# Espressif register map
File version: 1.0
CPU: Xtensa LX6 1, little endian, no MPU, FPU, 3 interrupt priority bits
Registers are 32-bit, access not given, reset 0x0 unless marked. A register's access mark holds for its fields unless they carry their own. Offsets are from the block's base; [hi:lo] are bit positions; {n}, {i} and the like mark numbered series.

## SENS
Base 0x3FF48800
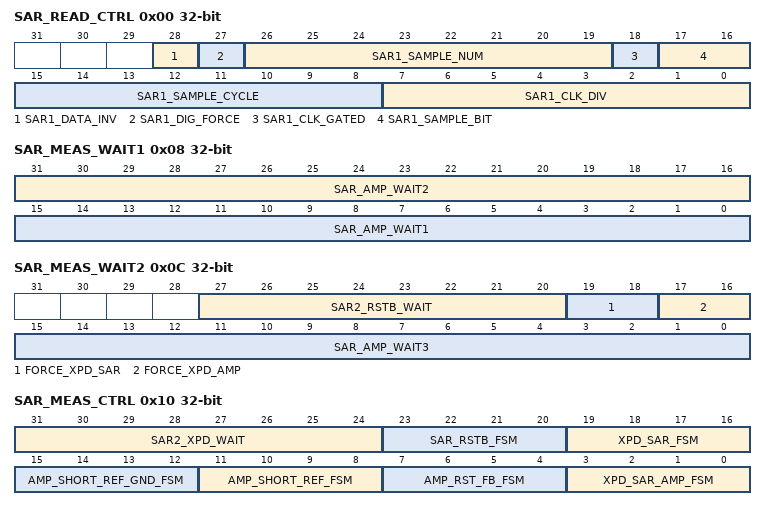
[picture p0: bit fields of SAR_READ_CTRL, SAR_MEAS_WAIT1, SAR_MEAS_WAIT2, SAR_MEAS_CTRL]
0x00 SAR_READ_CTRL — SENS_SAR_READ_CTRL
  [28] SAR1_DATA_INV, [27] SAR1_DIG_FORCE, [26:19] SAR1_SAMPLE_NUM, [18] SAR1_CLK_GATED, [17:16] SAR1_SAMPLE_BIT, [15:8] SAR1_SAMPLE_CYCLE, [7:0] SAR1_CLK_DIV
0x04 SAR_READ_STATUS1 — SENS_SAR_READ_STATUS1
  [31:0] SAR1_READER_STATUS
0x08 SAR_MEAS_WAIT1 — SENS_SAR_MEAS_WAIT1
  [31:16] SAR_AMP_WAIT2, [15:0] SAR_AMP_WAIT1
0x0C SAR_MEAS_WAIT2 — SENS_SAR_MEAS_WAIT2
  [27:20] SAR2_RSTB_WAIT, [19:18] FORCE_XPD_SAR, [17:16] FORCE_XPD_AMP, [15:0] SAR_AMP_WAIT3
0x10 SAR_MEAS_CTRL — SENS_SAR_MEAS_CTRL
  [31:24] SAR2_XPD_WAIT, [23:20] SAR_RSTB_FSM, [19:16] XPD_SAR_FSM, [15:12] AMP_SHORT_REF_GND_FSM, [11:8] AMP_SHORT_REF_FSM, [7:4] AMP_RST_FB_FSM, [3:0] XPD_SAR_AMP_FSM
0x14 SAR_READ_STATUS2 — SENS_SAR_READ_STATUS2
  [31:0] SAR2_READER_STATUS
{0x18+4i} ULP_CP_SLEEP_CYC{i} (i=0..4) — SENS_ULP_CP_SLEEP_CYC{i}
  [31:0] SLEEP_CYCLES_S{i}
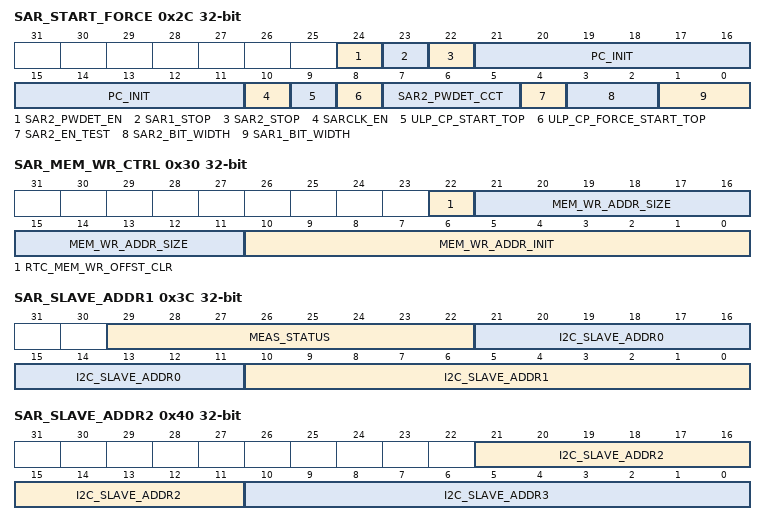
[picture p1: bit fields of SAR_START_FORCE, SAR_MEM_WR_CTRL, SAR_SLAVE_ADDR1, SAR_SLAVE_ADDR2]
0x2C SAR_START_FORCE — SENS_SAR_START_FORCE
  [24] SAR2_PWDET_EN, [23] SAR1_STOP, [22] SAR2_STOP, [21:11] PC_INIT, [10] SARCLK_EN, [9] ULP_CP_START_TOP, [8] ULP_CP_FORCE_START_TOP, [7:5] SAR2_PWDET_CCT, [4] SAR2_EN_TEST, [3:2] SAR2_BIT_WIDTH, [1:0] SAR1_BIT_WIDTH
0x30 SAR_MEM_WR_CTRL — SENS_SAR_MEM_WR_CTRL
  [22] RTC_MEM_WR_OFFST_CLR, [21:11] MEM_WR_ADDR_SIZE, [10:0] MEM_WR_ADDR_INIT
0x34 SAR_ATTEN1 — SENS_SAR_ATTEN1
  [31:0] SAR1_ATTEN
0x38 SAR_ATTEN2 — SENS_SAR_ATTEN2
  [31:0] SAR2_ATTEN
0x3C SAR_SLAVE_ADDR1 — SENS_SAR_SLAVE_ADDR1
  [29:22] MEAS_STATUS, [21:11] I2C_SLAVE_ADDR0, [10:0] I2C_SLAVE_ADDR1
0x40 SAR_SLAVE_ADDR2 — SENS_SAR_SLAVE_ADDR2
  [21:11] I2C_SLAVE_ADDR2, [10:0] I2C_SLAVE_ADDR3
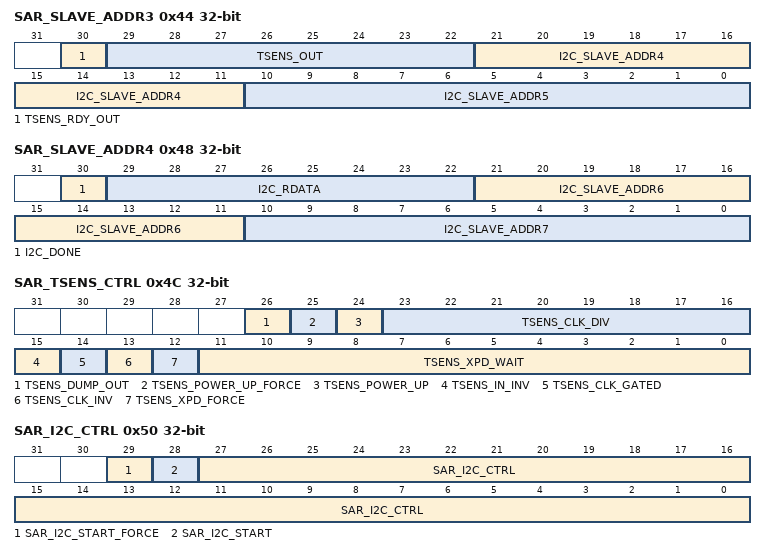
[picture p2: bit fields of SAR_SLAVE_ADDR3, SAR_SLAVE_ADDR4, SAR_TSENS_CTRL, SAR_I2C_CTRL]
0x44 SAR_SLAVE_ADDR3 — SENS_SAR_SLAVE_ADDR3
  [30] TSENS_RDY_OUT, [29:22] TSENS_OUT, [21:11] I2C_SLAVE_ADDR4, [10:0] I2C_SLAVE_ADDR5
0x48 SAR_SLAVE_ADDR4 — SENS_SAR_SLAVE_ADDR4
  [30] I2C_DONE, [29:22] I2C_RDATA, [21:11] I2C_SLAVE_ADDR6, [10:0] I2C_SLAVE_ADDR7
0x4C SAR_TSENS_CTRL — SENS_SAR_TSENS_CTRL
  [26] TSENS_DUMP_OUT, [25] TSENS_POWER_UP_FORCE, [24] TSENS_POWER_UP, [23:16] TSENS_CLK_DIV, [15] TSENS_IN_INV, [14] TSENS_CLK_GATED, [13] TSENS_CLK_INV, [12] TSENS_XPD_FORCE, [11:0] TSENS_XPD_WAIT
0x50 SAR_I2C_CTRL — SENS_SAR_I2C_CTRL
  [29] SAR_I2C_START_FORCE, [28] SAR_I2C_START, [27:0] SAR_I2C_CTRL
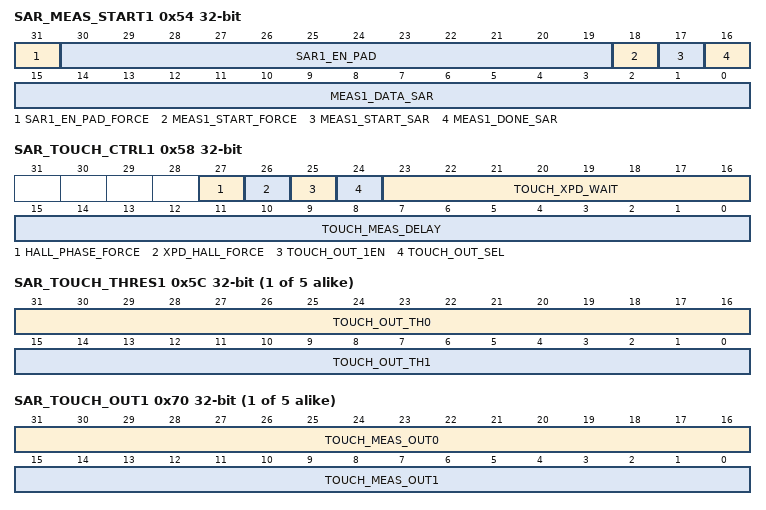
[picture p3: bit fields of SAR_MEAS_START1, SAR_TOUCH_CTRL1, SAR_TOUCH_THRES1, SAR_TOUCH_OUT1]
0x54 SAR_MEAS_START1 — SENS_SAR_MEAS_START1
  [31] SAR1_EN_PAD_FORCE, [30:19] SAR1_EN_PAD, [18] MEAS1_START_FORCE, [17] MEAS1_START_SAR, [16] MEAS1_DONE_SAR, [15:0] MEAS1_DATA_SAR
0x58 SAR_TOUCH_CTRL1 — SENS_SAR_TOUCH_CTRL1
  [27] HALL_PHASE_FORCE, [26] XPD_HALL_FORCE, [25] TOUCH_OUT_1EN, [24] TOUCH_OUT_SEL, [23:16] TOUCH_XPD_WAIT, [15:0] TOUCH_MEAS_DELAY
{0x58+4i} SAR_TOUCH_THRES{i} (i=1..5) — SENS_SAR_TOUCH_THRES{i}
  [31:16] TOUCH_OUT_TH{2i-2}, [15:0] TOUCH_OUT_TH{2i-1}
{0x6C+4i} SAR_TOUCH_OUT{i} (i=1..5) — SENS_SAR_TOUCH_OUT{i}
  [31:16] TOUCH_MEAS_OUT{2i-2}, [15:0] TOUCH_MEAS_OUT{2i-1}
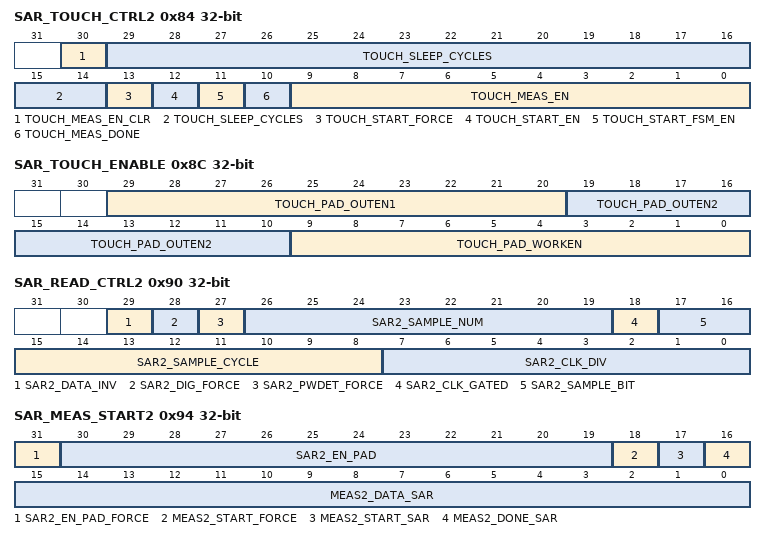
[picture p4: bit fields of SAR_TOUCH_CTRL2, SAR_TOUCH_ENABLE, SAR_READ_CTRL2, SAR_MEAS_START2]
0x84 SAR_TOUCH_CTRL2 — SENS_SAR_TOUCH_CTRL2
  [30] TOUCH_MEAS_EN_CLR, [29:14] TOUCH_SLEEP_CYCLES, [13] TOUCH_START_FORCE, [12] TOUCH_START_EN, [11] TOUCH_START_FSM_EN, [10] TOUCH_MEAS_DONE, [9:0] TOUCH_MEAS_EN
0x8C SAR_TOUCH_ENABLE — SENS_SAR_TOUCH_ENABLE
  [29:20] TOUCH_PAD_OUTEN1, [19:10] TOUCH_PAD_OUTEN2, [9:0] TOUCH_PAD_WORKEN
0x90 SAR_READ_CTRL2 — SENS_SAR_READ_CTRL2
  [29] SAR2_DATA_INV, [28] SAR2_DIG_FORCE, [27] SAR2_PWDET_FORCE, [26:19] SAR2_SAMPLE_NUM, [18] SAR2_CLK_GATED, [17:16] SAR2_SAMPLE_BIT, [15:8] SAR2_SAMPLE_CYCLE, [7:0] SAR2_CLK_DIV
0x94 SAR_MEAS_START2 — SENS_SAR_MEAS_START2
  [31] SAR2_EN_PAD_FORCE, [30:19] SAR2_EN_PAD, [18] MEAS2_START_FORCE, [17] MEAS2_START_SAR, [16] MEAS2_DONE_SAR, [15:0] MEAS2_DATA_SAR
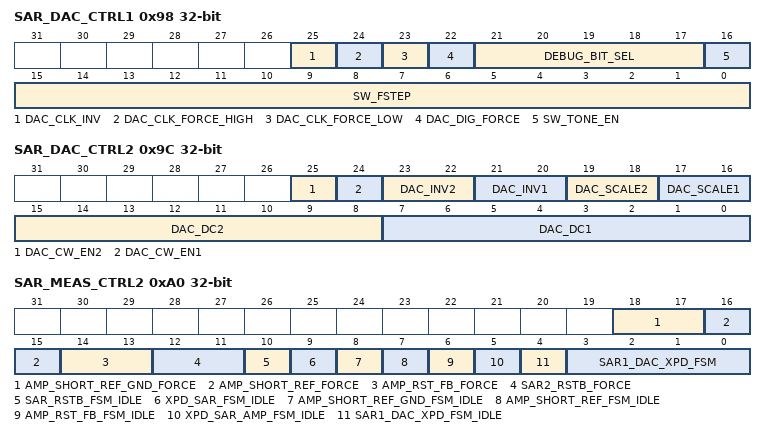
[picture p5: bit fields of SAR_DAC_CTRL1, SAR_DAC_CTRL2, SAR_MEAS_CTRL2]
0x98 SAR_DAC_CTRL1 — SENS_SAR_DAC_CTRL1
  [25] DAC_CLK_INV, [24] DAC_CLK_FORCE_HIGH, [23] DAC_CLK_FORCE_LOW, [22] DAC_DIG_FORCE, [21:17] DEBUG_BIT_SEL, [16] SW_TONE_EN, [15:0] SW_FSTEP
0x9C SAR_DAC_CTRL2 — SENS_SAR_DAC_CTRL2
  [25] DAC_CW_EN2, [24] DAC_CW_EN1, [23:22] DAC_INV2, [21:20] DAC_INV1, [19:18] DAC_SCALE2, [17:16] DAC_SCALE1, [15:8] DAC_DC2, [7:0] DAC_DC1
0xA0 SAR_MEAS_CTRL2 — SENS_SAR_MEAS_CTRL2
  [18:17] AMP_SHORT_REF_GND_FORCE, [16:15] AMP_SHORT_REF_FORCE, [14:13] AMP_RST_FB_FORCE, [12:11] SAR2_RSTB_FORCE, [10] SAR_RSTB_FSM_IDLE, [9] XPD_SAR_FSM_IDLE, [8] AMP_SHORT_REF_GND_FSM_IDLE, [7] AMP_SHORT_REF_FSM_IDLE, [6] AMP_RST_FB_FSM_IDLE, [5] XPD_SAR_AMP_FSM_IDLE, [4] SAR1_DAC_XPD_FSM_IDLE, [3:0] SAR1_DAC_XPD_FSM
0xF8 SAR_NOUSE — SENS_SAR_NOUSE
0xFC SARDATE — SENS_SARDATE
  [27:0] SAR_DATE
